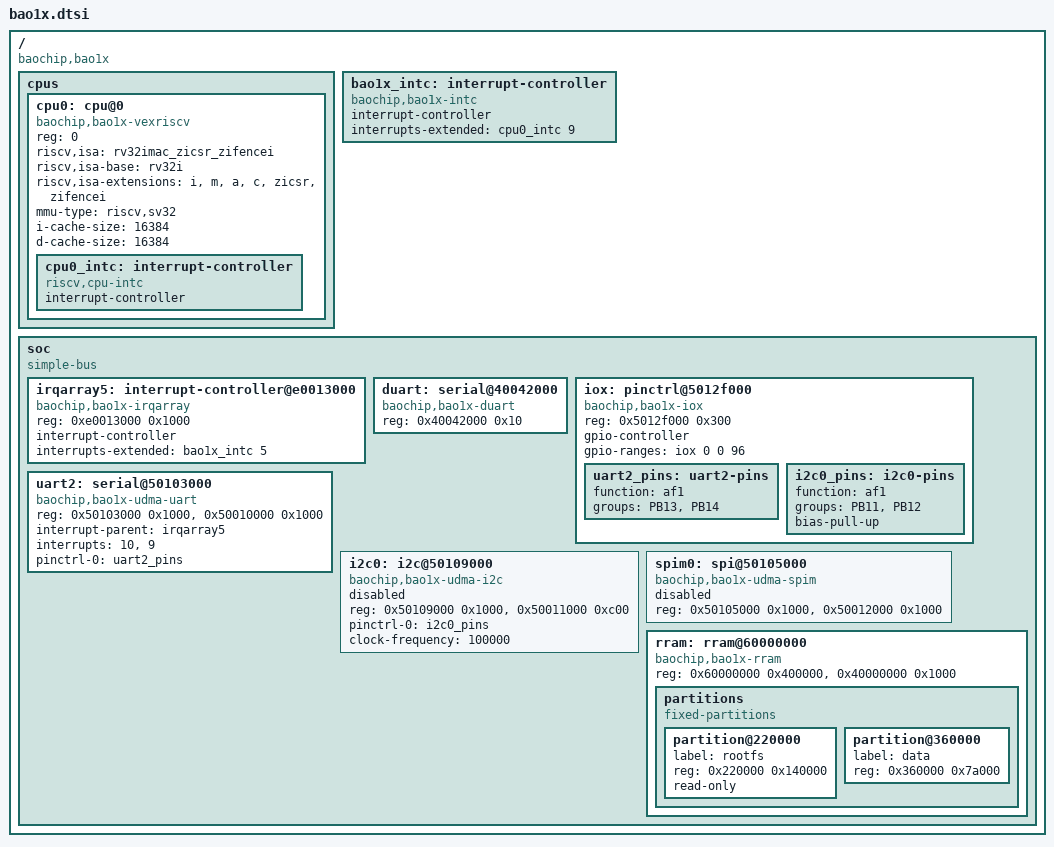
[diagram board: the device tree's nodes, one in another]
/*
 * Baochip-1x SoC. Phase-3 scope: only nodes with kernel consumers.
 * (Peripheral nodes + bindings land together with their drivers.)
 *
 * The CPU has no time CSR: rdtime is emulated by bao1x-sbi from mcycle,
 * so timebase-frequency must equal the core clock and is board-specific
 * (Renode virtual clock vs 350MHz silicon).
 *
 * SPDX-License-Identifier: GPL-2.0 OR MIT
 */

/ {
	compatible = "baochip,bao1x";
	#address-cells = <1>;
	#size-cells = <1>;

	cpus {
		#address-cells = <1>;
		#size-cells = <0>;

		cpu0: cpu@0 {
			device_type = "cpu";
			compatible = "baochip,bao1x-vexriscv", "riscv";
			reg = <0>;
			status = "okay";
			riscv,isa = "rv32imac_zicsr_zifencei";
			riscv,isa-base = "rv32i";
			riscv,isa-extensions = "i", "m", "a", "c", "zicsr",
					       "zifencei";
			mmu-type = "riscv,sv32";
			i-cache-size = <16384>;
			d-cache-size = <16384>;

			cpu0_intc: interrupt-controller {
				#interrupt-cells = <1>;
				compatible = "riscv,cpu-intc";
				interrupt-controller;
			};
		};
	};

	/* VexRiscv 32-line external interrupt array: CSR-controlled
	 * (supervisor mask 0x9C0 / pending 0xDC0), no MMIO registers. */
	bao1x_intc: interrupt-controller {
		compatible = "baochip,bao1x-intc";
		interrupt-controller;
		#interrupt-cells = <1>;
		interrupts-extended = <&cpu0_intc 9>;
	};

	soc {
		compatible = "simple-bus";
		#address-cells = <1>;
		#size-cells = <1>;
		ranges;

		/* Bank 5 aggregates the four uDMA UARTs (events 4n..4n+3:
		 * rx dma, tx dma, rx char, err). Banks 0-4 and 6-19 follow
		 * as their consumers gain drivers. */
		irqarray5: interrupt-controller@e0013000 {
			compatible = "baochip,bao1x-irqarray";
			reg = <0xe0013000 0x1000>;
			interrupt-controller;
			#interrupt-cells = <1>;
			interrupts-extended = <&bao1x_intc 5>;
		};

		duart: serial@40042000 {
			/* TX-only debug UART; earlycon only. */
			compatible = "baochip,bao1x-duart";
			reg = <0x40042000 0x10>;
		};

		iox: pinctrl@5012f000 {
			compatible = "baochip,bao1x-iox";
			reg = <0x5012f000 0x300>;
			gpio-controller;
			#gpio-cells = <2>;
			gpio-ranges = <&iox 0 0 96>;

			uart2_pins: uart2-pins {
				/* PB13 rx / PB14 tx; also set by boot1. */
				function = "af1";
				groups = "PB13", "PB14";
			};

			i2c0_pins: i2c0-pins {
				/* PB11 SCL / PB12 SDA */
				function = "af1";
				groups = "PB11", "PB12";
				bias-pull-up;
			};
		};

		uart2: serial@50103000 {
			compatible = "baochip,bao1x-udma-uart";
			/* Registers + a private IFRAM0 slice: the uDMA
			 * transmitter can only fetch from IFRAM. */
			reg = <0x50103000 0x1000>, <0x50010000 0x1000>;
			reg-names = "regs", "txram";
			interrupt-parent = <&irqarray5>;
			interrupts = <10>, <9>;
			interrupt-names = "rx", "tx";
			pinctrl-names = "default";
			pinctrl-0 = <&uart2_pins>;
			/* clock-frequency (perclk) is board-provided. */
		};

		i2c0: i2c@50109000 {
			compatible = "baochip,bao1x-udma-i2c";
			/* Registers + an IFRAM0 slice for the cmd/TX/RX
			 * uDMA bounce buffers. */
			reg = <0x50109000 0x1000>, <0x50011000 0xc00>;
			reg-names = "regs", "ifram";
			#address-cells = <1>;
			#size-cells = <0>;
			pinctrl-names = "default";
			pinctrl-0 = <&i2c0_pins>;
			clock-frequency = <100000>;
			/* clocks (perclk) provided by the board. */
			status = "disabled";
		};

		spim0: spi@50105000 {
			compatible = "baochip,bao1x-udma-spim";
			/* Registers + an IFRAM0 slice for the cmd/TX/RX
			 * uDMA bounce buffers. */
			reg = <0x50105000 0x1000>, <0x50012000 0x1000>;
			reg-names = "regs", "ifram";
			#address-cells = <1>;
			#size-cells = <0>;
			/* No SPIM is wired on the Dabao by default; boards
			 * enable and add pinctrl when they route one. */
			status = "disabled";
		};

		rram: rram@60000000 {
			/* Memory-mapped XIP reads; writes via the RRC line
			 * buffer. Only the partitions below are exposed —
			 * boot0/boot1/shim/kernel stay unreachable, and
			 * 0x3da000..0x400000 is vendor-reserved (secrets;
			 * never map a writable partition there). */
			compatible = "baochip,bao1x-rram";
			reg = <0x60000000 0x400000>, <0x40000000 0x1000>;
			reg-names = "array", "rrc";

			partitions {
				compatible = "fixed-partitions";
				#address-cells = <1>;
				#size-cells = <1>;

				partition@220000 {
					label = "rootfs";
					reg = <0x220000 0x140000>;
					read-only;
				};

				partition@360000 {
					label = "data";
					reg = <0x360000 0x7a000>;
				};
			};
		};
	};
};
